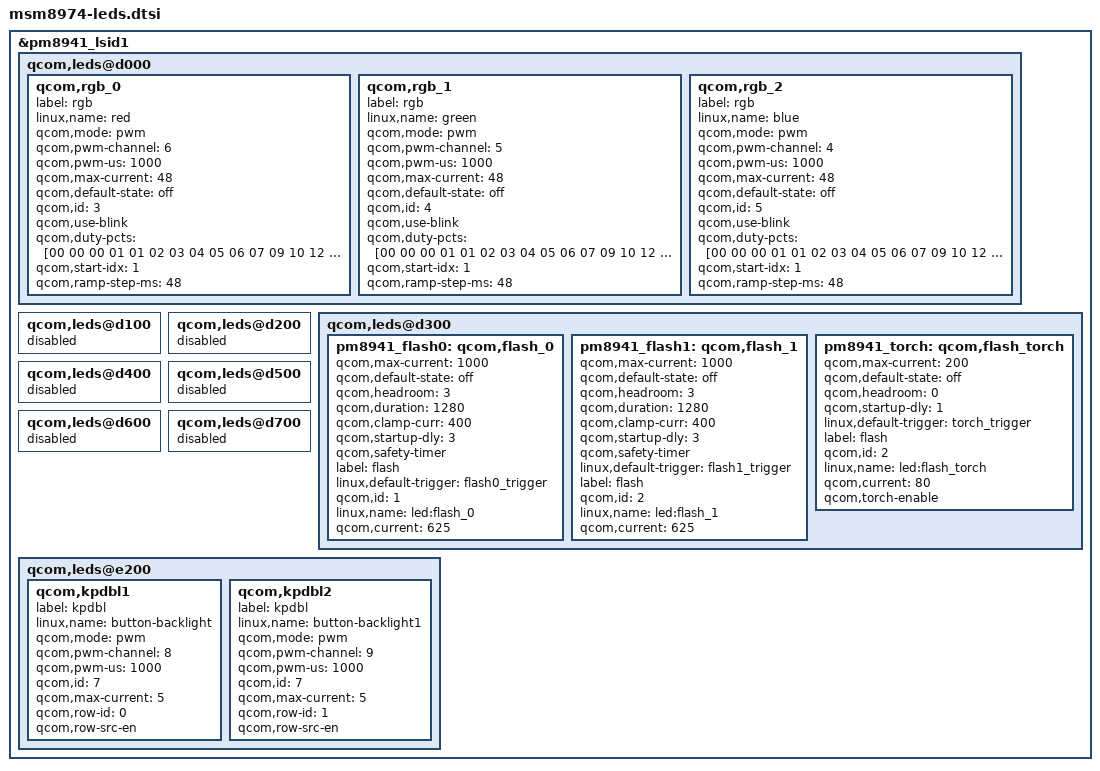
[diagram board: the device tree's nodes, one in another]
/*
 * Copyright (c) 2012-2013, The Linux Foundation. All rights reserved.
 * Copyright (C) 2017 XiaoMi, Inc.
 *
 * This program is free software; you can redistribute it and/or modify
 * it under the terms of the GNU General Public License version 2 and
 * only version 2 as published by the Free Software Foundation.
 *
 * This program is distributed in the hope that it will be useful,
 * but WITHOUT ANY WARRANTY; without even the implied warranty of
 * MERCHANTABILITY or FITNESS FOR A PARTICULAR PURPOSE.  See the
 * GNU General Public License for more details.
 */

&pm8941_lsid1 {
	qcom,leds@d000 {
		status = "okay";
		qcom,rgb_0 {
			label = "rgb";
			linux,name = "red";
			qcom,mode = "pwm";
			qcom,pwm-channel = <6>;
			qcom,pwm-us = <1000>;
			qcom,max-current = <48>;
			qcom,default-state = "off";
			qcom,id = <3>;
			qcom,use-blink;
			qcom,duty-pcts = [00 00 00 01 01 02 03 04 05 06 07 09 10
					12 13 15 16 18 19 21 22 24 25 26 27
					28 28 29 29 30 30 30 29 29 28 28 27
					26 25 24 22 21 19 18 16 15 13 12 10
					09 07 06 05 04 03 02 01 01 00 00];
			qcom,start-idx = <1>;
			qcom,ramp-step-ms = <48>;
		};

		qcom,rgb_1 {
			label = "rgb";
			linux,name = "green";
			qcom,mode = "pwm";
			qcom,pwm-channel = <5>;
			qcom,pwm-us = <1000>;
			qcom,max-current = <48>;
			qcom,default-state = "off";
			qcom,id = <4>;
			qcom,use-blink;
			qcom,duty-pcts = [00 00 00 01 01 02 03 04 05 06 07 09 10
					12 13 15 16 18 19 21 22 24 25 26 27
					28 28 29 29 30 30 30 29 29 28 28 27
					26 25 24 22 21 19 18 16 15 13 12 10
					09 07 06 05 04 03 02 01 01 00 00];
			qcom,start-idx = <1>;
			qcom,ramp-step-ms = <48>;
		};

		qcom,rgb_2 {
			label = "rgb";
			linux,name = "blue";
			qcom,mode = "pwm";
			qcom,pwm-channel = <4>;
			qcom,pwm-us = <1000>;
			qcom,max-current = <48>;
			qcom,default-state = "off";
			qcom,id = <5>;
			qcom,use-blink;
				qcom,duty-pcts = [00 00 00 01 01 02 03 04 05 06 07 09 10
					12 13 15 16 18 19 21 22 24 25 26 27
					28 28 29 29 30 30 30 29 29 28 28 27
					26 25 24 22 21 19 18 16 15 13 12 10
					09 07 06 05 04 03 02 01 01 00 00];
			qcom,start-idx = <1>;
			qcom,ramp-step-ms = <48>;
		};
	};

	qcom,leds@d100 {
		status = "disabled";
	};

	qcom,leds@d200 {
		status = "disabled";
	};

	qcom,leds@d300 {
		status = "okay";
		pm8941_flash0: qcom,flash_0 {
			qcom,max-current = <1000>;
			qcom,default-state = "off";
			qcom,headroom = <3>;
			qcom,duration = <1280>;
			qcom,clamp-curr = <400>;
			qcom,startup-dly = <3>;
			qcom,safety-timer;
			label = "flash";
			linux,default-trigger =
				"flash0_trigger";
			qcom,id = <1>;
			linux,name = "led:flash_0";
			qcom,current = <625>;
		};

		pm8941_flash1: qcom,flash_1 {
			qcom,max-current = <1000>;
			qcom,default-state = "off";
			qcom,headroom = <3>;
			qcom,duration = <1280>;
			qcom,clamp-curr = <400>;
			qcom,startup-dly = <3>;
			qcom,safety-timer;
			linux,default-trigger =
				"flash1_trigger";
			label = "flash";
			qcom,id = <2>;
			linux,name = "led:flash_1";
			qcom,current = <625>;
		};

		pm8941_torch: qcom,flash_torch {
			qcom,max-current = <200>;
			qcom,default-state = "off";
			qcom,headroom = <0>;
			qcom,startup-dly = <1>;
			linux,default-trigger =
				"torch_trigger";
			label = "flash";
			qcom,id = <2>;
			linux,name = "led:flash_torch";
			qcom,current = <80>;
			qcom,torch-enable;
		};
	};

	qcom,leds@d400 {
		status = "disabled";
	};

	qcom,leds@d500 {
		status = "disabled";
	};

	qcom,leds@d600 {
		status = "disabled";
	};

	qcom,leds@d700 {
		status = "disabled";
	};

	qcom,leds@e200 {
		status = "okay";

		qcom,kpdbl1 {
			label = "kpdbl";
			linux,name = "button-backlight";
			qcom,mode = "pwm";
			qcom,pwm-channel = <8>;
			qcom,pwm-us = <1000>;
			qcom,id = <7>;
			qcom,max-current = <5>;
			qcom,row-id = <0>;
			qcom,row-src-en;
		};

		qcom,kpdbl2 {
			label = "kpdbl";
			linux,name = "button-backlight1";
			qcom,mode = "pwm";
			qcom,pwm-channel = <9>;
			qcom,pwm-us = <1000>;
			qcom,id = <7>;
			qcom,max-current = <5>;
			qcom,row-id = <1>;
			qcom,row-src-en;
		};
	};
};
